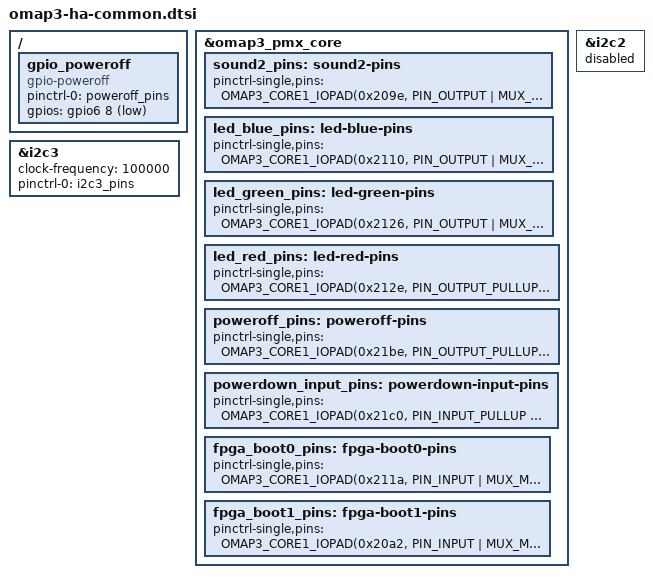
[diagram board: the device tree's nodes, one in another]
#include "omap3-tao3530.dtsi"
/ {
	gpio_poweroff {
		pinctrl-names = "default";
		pinctrl-0 = <&poweroff_pins>;
		compatible = "gpio-poweroff";
		gpios = <&gpio6 8 GPIO_ACTIVE_LOW>;	 
	};
};
&omap3_pmx_core {
	sound2_pins: sound2-pins {
		pinctrl-single,pins = <
			OMAP3_CORE1_IOPAD(0x209e, PIN_OUTPUT | MUX_MODE4)	 
		>;
	};
	led_blue_pins: led-blue-pins {
		pinctrl-single,pins = <
			OMAP3_CORE1_IOPAD(0x2110, PIN_OUTPUT | MUX_MODE4)	 
		>;
	};
	led_green_pins: led-green-pins {
		pinctrl-single,pins = <
			OMAP3_CORE1_IOPAD(0x2126, PIN_OUTPUT | MUX_MODE4)	 
		>;
	};
	led_red_pins: led-red-pins {
		pinctrl-single,pins = <
			OMAP3_CORE1_IOPAD(0x212e, PIN_OUTPUT_PULLUP | MUX_MODE4)	 
		>;
	};
	poweroff_pins: poweroff-pins {
		pinctrl-single,pins = <
			OMAP3_CORE1_IOPAD(0x21be, PIN_OUTPUT_PULLUP | MUX_MODE4)	 
		>;
	};
	powerdown_input_pins: powerdown-input-pins {
		pinctrl-single,pins = <
			OMAP3_CORE1_IOPAD(0x21c0, PIN_INPUT_PULLUP | MUX_MODE4)	 
		>;
	};
	fpga_boot0_pins: fpga-boot0-pins {
		pinctrl-single,pins = <
			OMAP3_CORE1_IOPAD(0x211a, PIN_INPUT | MUX_MODE4)	 
			OMAP3_CORE1_IOPAD(0x211c, PIN_OUTPUT | MUX_MODE4)	 
			OMAP3_CORE1_IOPAD(0x211e, PIN_OUTPUT | MUX_MODE4)	 
			OMAP3_CORE1_IOPAD(0x2120, PIN_INPUT_PULLUP | MUX_MODE4)	 
		>;
	};
	fpga_boot1_pins: fpga-boot1-pins {
		pinctrl-single,pins = <
			OMAP3_CORE1_IOPAD(0x20a2, PIN_INPUT | MUX_MODE4)	 
			OMAP3_CORE1_IOPAD(0x20a4, PIN_OUTPUT | MUX_MODE4)	 
			OMAP3_CORE1_IOPAD(0x20a6, PIN_OUTPUT | MUX_MODE4)	 
			OMAP3_CORE1_IOPAD(0x20a8, PIN_INPUT_PULLUP | MUX_MODE4)	 
		>;
	};
};
&i2c2 {
	status = "disabled";
};
&i2c3 {
	clock-frequency = <100000>;
	pinctrl-names = "default";
	pinctrl-0 = <&i2c3_pins>;
};
